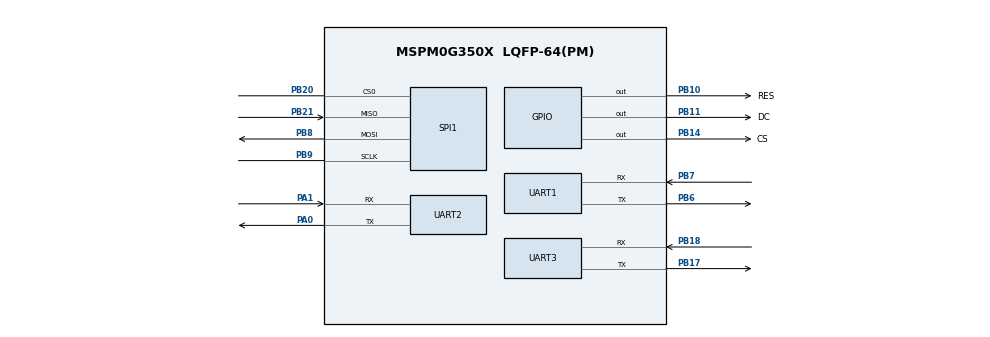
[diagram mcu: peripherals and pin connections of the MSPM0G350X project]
/**
 * @cliArgs --device "MSPM0G350X" --part "Default" --package "LQFP-64(PM)" --product "mspm0_sdk@2.10.00.04"
 * @versions {"tool":"1.26.2+4477"}
 */

/**
 * Import the modules used in this configuration.
 */
const GPIO   = scripting.addModule("/ti/driverlib/GPIO", {}, false);
const GPIO1  = GPIO.addInstance();
const SPI    = scripting.addModule("/ti/driverlib/SPI", {}, false);
const SPI1   = SPI.addInstance();
const SYSCTL = scripting.addModule("/ti/driverlib/SYSCTL");
const TIMER  = scripting.addModule("/ti/driverlib/TIMER", {}, false);
const TIMER1 = TIMER.addInstance();
const UART   = scripting.addModule("/ti/driverlib/UART", {}, false);
const UART1  = UART.addInstance();
const UART2  = UART.addInstance();
const UART3  = UART.addInstance();

/**
 * Write custom configuration values to the imported modules.
 */
const divider9       = system.clockTree["UDIV"];
divider9.divideValue = 2;

const multiplier2         = system.clockTree["PLL_QDIV"];
multiplier2.multiplyValue = 4;

const mux4       = system.clockTree["EXHFMUX"];
mux4.inputSelect = "EXHFMUX_XTAL";

const mux8       = system.clockTree["HSCLKMUX"];
mux8.inputSelect = "HSCLKMUX_SYSPLL0";

const mux12       = system.clockTree["SYSPLLMUX"];
mux12.inputSelect = "zSYSPLLMUX_HFCLK";

const pinFunction4        = system.clockTree["HFXT"];
pinFunction4.inputFreq    = 40;
pinFunction4.enable       = true;
pinFunction4.HFCLKMonitor = true;
pinFunction4.HFXTStartup  = 20;

GPIO1.$name                         = "OLED";
GPIO1.associatedPins.create(3);
GPIO1.associatedPins[0].$name       = "RES";
GPIO1.associatedPins[0].pin.$assign = "PB10";
GPIO1.associatedPins[1].$name       = "DC";
GPIO1.associatedPins[1].pin.$assign = "PB11";
GPIO1.associatedPins[2].$name       = "CS";
GPIO1.associatedPins[2].pin.$assign = "PB14";

const Board = scripting.addModule("/ti/driverlib/Board", {}, false);

SPI1.$name                              = "SPI_OLED";
SPI1.targetBitRate                      = 20000000;
SPI1.peripheral.$assign                 = "SPI1";
SPI1.peripheral.sclkPin.$assign         = "PB9";
SPI1.peripheral.mosiPin.$assign         = "PB8";
SPI1.peripheral.misoPin.$assign         = "PB21";
SPI1.peripheral.cs0Pin.$assign          = "PB20";
SPI1.sclkPinConfig.direction            = scripting.forceWrite("OUTPUT");
SPI1.sclkPinConfig.onlyInternalResistor = scripting.forceWrite(false);
SPI1.sclkPinConfig.passedPeripheralType = scripting.forceWrite("Digital");
SPI1.sclkPinConfig.$name                = "ti_driverlib_gpio_GPIOPinGeneric6";
SPI1.mosiPinConfig.direction            = scripting.forceWrite("OUTPUT");
SPI1.mosiPinConfig.hideOutputInversion  = scripting.forceWrite(false);
SPI1.mosiPinConfig.onlyInternalResistor = scripting.forceWrite(false);
SPI1.mosiPinConfig.passedPeripheralType = scripting.forceWrite("Digital");
SPI1.mosiPinConfig.$name                = "ti_driverlib_gpio_GPIOPinGeneric7";
SPI1.misoPinConfig.onlyInternalResistor = scripting.forceWrite(false);
SPI1.misoPinConfig.passedPeripheralType = scripting.forceWrite("Digital");
SPI1.misoPinConfig.$name                = "ti_driverlib_gpio_GPIOPinGeneric8";
SPI1.cs0PinConfig.direction             = scripting.forceWrite("OUTPUT");
SPI1.cs0PinConfig.hideOutputInversion   = scripting.forceWrite(false);
SPI1.cs0PinConfig.onlyInternalResistor  = scripting.forceWrite(false);
SPI1.cs0PinConfig.passedPeripheralType  = scripting.forceWrite("Digital");
SPI1.cs0PinConfig.$name                 = "ti_driverlib_gpio_GPIOPinGeneric9";

SYSCTL.forceDefaultClkConfig = true;
SYSCTL.clockTreeEn           = true;

TIMER1.$name            = "TIMER_0";
TIMER1.timerStartTimer  = true;
TIMER1.timerMode        = "PERIODIC";
TIMER1.timerClkDiv      = 8;
TIMER1.timerClkPrescale = 100;
TIMER1.timerPeriod      = "1 ms";
TIMER1.interrupts       = ["ZERO"];

UART1.targetBaudRate                   = 115200;
UART1.$name                            = "K230";
UART1.enabledInterrupts                = ["RX"];
UART1.peripheral.$assign               = "UART1";
UART1.peripheral.rxPin.$assign         = "PB7";
UART1.peripheral.txPin.$assign         = "PB6";
UART1.txPinConfig.direction            = scripting.forceWrite("OUTPUT");
UART1.txPinConfig.hideOutputInversion  = scripting.forceWrite(false);
UART1.txPinConfig.onlyInternalResistor = scripting.forceWrite(false);
UART1.txPinConfig.passedPeripheralType = scripting.forceWrite("Digital");
UART1.txPinConfig.$name                = "ti_driverlib_gpio_GPIOPinGeneric0";
UART1.rxPinConfig.hideOutputInversion  = scripting.forceWrite(false);
UART1.rxPinConfig.onlyInternalResistor = scripting.forceWrite(false);
UART1.rxPinConfig.passedPeripheralType = scripting.forceWrite("Digital");
UART1.rxPinConfig.$name                = "ti_driverlib_gpio_GPIOPinGeneric1";

UART2.enabledDMATXTriggers                 = "DL_UART_DMA_INTERRUPT_TX";
UART2.enabledDMARXTriggers                 = "DL_UART_DMA_INTERRUPT_RX";
UART2.$name                                = "STEPPER";
UART2.targetBaudRate                       = 115200;
UART2.peripheral.$assign                   = "UART0";
UART2.peripheral.rxPin.$assign             = "PA1";
UART2.peripheral.txPin.$assign             = "PA0";
UART2.txPinConfig.direction                = scripting.forceWrite("OUTPUT");
UART2.txPinConfig.hideOutputInversion      = scripting.forceWrite(false);
UART2.txPinConfig.onlyInternalResistor     = scripting.forceWrite(false);
UART2.txPinConfig.passedPeripheralType     = scripting.forceWrite("Digital");
UART2.txPinConfig.$name                    = "ti_driverlib_gpio_GPIOPinGeneric2";
UART2.rxPinConfig.hideOutputInversion      = scripting.forceWrite(false);
UART2.rxPinConfig.onlyInternalResistor     = scripting.forceWrite(false);
UART2.rxPinConfig.passedPeripheralType     = scripting.forceWrite("Digital");
UART2.rxPinConfig.$name                    = "ti_driverlib_gpio_GPIOPinGeneric3";
UART2.DMA_CHANNEL_TX.addressMode           = "b2f";
UART2.DMA_CHANNEL_TX.srcLength             = "BYTE";
UART2.DMA_CHANNEL_TX.configureTransferSize = true;
UART2.DMA_CHANNEL_TX.dstLength             = "BYTE";
UART2.DMA_CHANNEL_TX.$name                 = "STEPPER_TX";
UART2.DMA_CHANNEL_TX.peripheral.$assign    = "DMA_CH0";
UART2.DMA_CHANNEL_RX.srcLength             = "BYTE";
UART2.DMA_CHANNEL_RX.dstLength             = "BYTE";
UART2.DMA_CHANNEL_RX.addressMode           = "f2b";
UART2.DMA_CHANNEL_RX.configureTransferSize = true;
UART2.DMA_CHANNEL_RX.$name                 = "STEPPER_RX";

UART3.$name                                = "BT";
UART3.enabledDMARXTriggers                 = "DL_UART_DMA_INTERRUPT_RX";
UART3.enabledDMATXTriggers                 = "DL_UART_DMA_INTERRUPT_TX";
UART3.peripheral.$assign                   = "UART2";
UART3.peripheral.rxPin.$assign             = "PB18";
UART3.peripheral.txPin.$assign             = "PB17";
UART3.txPinConfig.direction                = scripting.forceWrite("OUTPUT");
UART3.txPinConfig.hideOutputInversion      = scripting.forceWrite(false);
UART3.txPinConfig.onlyInternalResistor     = scripting.forceWrite(false);
UART3.txPinConfig.passedPeripheralType     = scripting.forceWrite("Digital");
UART3.txPinConfig.$name                    = "ti_driverlib_gpio_GPIOPinGeneric4";
UART3.rxPinConfig.hideOutputInversion      = scripting.forceWrite(false);
UART3.rxPinConfig.onlyInternalResistor     = scripting.forceWrite(false);
UART3.rxPinConfig.passedPeripheralType     = scripting.forceWrite("Digital");
UART3.rxPinConfig.$name                    = "ti_driverlib_gpio_GPIOPinGeneric5";
UART3.DMA_CHANNEL_RX.$name                 = "BT_RX";
UART3.DMA_CHANNEL_RX.srcLength             = "BYTE";
UART3.DMA_CHANNEL_RX.dstLength             = "BYTE";
UART3.DMA_CHANNEL_RX.addressMode           = "f2b";
UART3.DMA_CHANNEL_RX.configureTransferSize = true;
UART3.DMA_CHANNEL_TX.$name                 = "BT_TX";
UART3.DMA_CHANNEL_TX.srcLength             = "BYTE";
UART3.DMA_CHANNEL_TX.dstLength             = "BYTE";
UART3.DMA_CHANNEL_TX.configureTransferSize = true;
UART3.DMA_CHANNEL_TX.addressMode           = "b2f";

/**
 * Pinmux solution for unlocked pins/peripherals. This ensures that minor changes to the automatic solver in a future
 * version of the tool will not impact the pinmux you originally saw.  These lines can be completely deleted in order to
 * re-solve from scratch.
 */
pinFunction4.peripheral.$suggestSolution           = "SYSCTL";
pinFunction4.peripheral.hfxInPin.$suggestSolution  = "PA5";
pinFunction4.peripheral.hfxOutPin.$suggestSolution = "PA6";
Board.peripheral.$suggestSolution                  = "DEBUGSS";
Board.peripheral.swclkPin.$suggestSolution         = "PA20";
Board.peripheral.swdioPin.$suggestSolution         = "PA19";
TIMER1.peripheral.$suggestSolution                 = "TIMA0";
UART2.DMA_CHANNEL_RX.peripheral.$suggestSolution   = "DMA_CH3";
UART3.DMA_CHANNEL_RX.peripheral.$suggestSolution   = "DMA_CH2";
UART3.DMA_CHANNEL_TX.peripheral.$suggestSolution   = "DMA_CH1";
